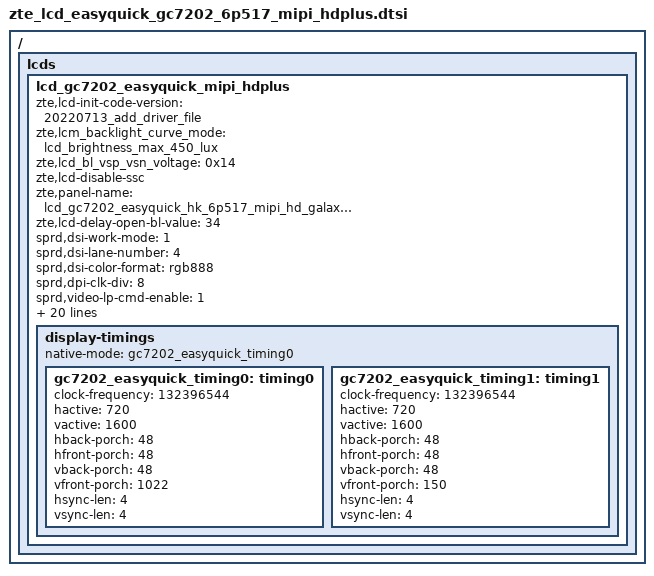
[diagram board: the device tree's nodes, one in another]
/ {
	fragment {
		target-path = "/";
		__overlay__ {
			lcds {
				lcd_gc7202_easyquick_mipi_hdplus: lcd_gc7202_easyquick_mipi_hdplus {
					zte,lcd-init-code-version = "20220713_add_driver_file";

					zte,lcm_backlight_curve_mode = "lcd_brightness_max_450_lux";
					zte,lcd_bl_vsp_vsn_voltage = <0x14>;
					zte,lcd-disable-ssc;
					zte,panel-name = "lcd_gc7202_easyquick_hk_6p517_mipi_hd_galaxycore_4lane";
					zte,lcd-delay-open-bl-value = <34>;

					sprd,dsi-work-mode = <1>;
					sprd,dsi-lane-number = <4>;
					sprd,dsi-color-format = "rgb888";

					sprd,dpi-clk-div = <8>;
					sprd,video-lp-cmd-enable = <1>;
					sprd,hporch-lp-disable = <1>;

					sprd,phy-bit-clock = <1059173>;
					sprd,phy-escape-clock = <20000>;/* kHz */

					sprd,width-mm = <67932>;
					sprd,height-mm = <150960>;

					sprd,esd-check-enable = <1>;/* 0:close , 1:open */
					sprd,esd-check-mode = <1>;/* 0:REG ,1:TE  */
					sprd,esd-check-period = <2000>;

		sprd,reset-on-sequence = <1 10>, <0 10>, <1 35>, <0 10>, <1 10>, <0 10>, <1 10>, <0 10>, <1 30>;
		sprd,reset-off-sequence = <1 10>;
		sprd,use-dcs-write;
		sprd,initial-command = [
39 00 00 04 FF 55 AA 66
15 00 00 02 FF 20
15 00 00 02 FB 00
15 00 00 02 FF 21
15 00 00 02 FB 00
15 00 00 02 FF 22
15 00 00 02 FB 00
15 00 00 02 FF 23
15 00 00 02 FB 00
15 00 00 02 FF 24
15 00 00 02 FB 00
15 00 00 02 FF 26
15 00 00 02 FB 00
15 00 00 02 FF 27
15 00 00 02 FB 00
15 00 00 02 FF A3
15 00 00 02 FB 00
15 00 00 02 FF B3
15 00 00 02 FB 00
15 00 00 02 FF C3
15 00 00 02 FB 00
15 00 00 02 FF 10
15 00 00 02 FB 00
15 00 00 02 FF 20
15 00 00 02 18 44
15 00 00 02 17 52
15 00 00 02 15 5d
15 00 00 02 12 A1
15 00 00 02 A5 00
15 00 00 02 A6 FF
15 00 00 02 A9 00
15 00 00 02 AA FF
15 00 00 02 D3 05
15 00 00 02 2D 1F
15 00 00 02 FF B3
15 00 00 02 58 84
15 00 00 02 82 1A
15 00 00 02 FF 22
15 00 00 02 1F 06
15 00 00 02 FF C3
15 00 00 02 06 44
15 00 00 02 13 07
15 00 00 02 FF 20
15 00 00 02 A3 46
15 00 00 02 A7 46
15 00 00 02 FF B3
15 00 00 02 3F 37
15 00 00 02 5E 10
15 00 00 02 FF 22
15 00 00 02 E4 01
15 00 00 02 01 06
15 00 00 02 02 40
15 00 00 02 25 08
15 00 00 02 26 00
15 00 00 02 2E Aa
15 00 00 02 2F 00
15 00 00 02 36 09
15 00 00 02 37 00
15 00 00 02 3F Aa
15 00 00 02 40 00
15 00 00 02 DC 00
/*15 00 00 02 E0 07//output test pin*/
15 00 00 02 FF 21
15 00 00 02 01 25
15 00 00 02 02 25
15 00 00 02 03 23
15 00 00 02 04 23
15 00 00 02 05 1B
15 00 00 02 06 03
15 00 00 02 07 18
15 00 00 02 08 19
15 00 00 02 09 1A
15 00 00 02 0A 09
15 00 00 02 0B 0B
15 00 00 02 0C 0D
15 00 00 02 0D 0F
15 00 00 02 0E 01
15 00 00 02 0F 25
15 00 00 02 10 25
15 00 00 02 11 25
15 00 00 02 12 25
15 00 00 02 13 25
15 00 00 02 14 25
15 00 00 02 15 25
15 00 00 02 16 25
15 00 00 02 17 23
15 00 00 02 18 23
15 00 00 02 19 23
15 00 00 02 1A 23
15 00 00 02 1B 1B
15 00 00 02 1C 02
15 00 00 02 1D 18
15 00 00 02 1E 19
15 00 00 02 1F 1A
15 00 00 02 20 08
15 00 00 02 21 0A
15 00 00 02 22 0C
15 00 00 02 23 0E
15 00 00 02 24 00
15 00 00 02 25 25
15 00 00 02 26 25
15 00 00 02 27 25
15 00 00 02 28 25
15 00 00 02 29 25
15 00 00 02 2A 25
15 00 00 02 2B 25
15 00 00 02 2D 25
15 00 00 02 7E 03
15 00 00 02 7F 23
15 00 00 02 8B 23
15 00 00 02 80 07
15 00 00 02 8C 03
15 00 00 02 81 03
15 00 00 02 8D 07
15 00 00 02 AF 40
15 00 00 02 B0 40
15 00 00 02 83 02
15 00 00 02 8F 02
15 00 00 02 84 10
15 00 00 02 90 10
15 00 00 02 85 58
15 00 00 02 91 58
15 00 00 02 87 02
15 00 00 02 93 06
15 00 00 02 82 B0
15 00 00 02 8E B0
15 00 00 02 2B 00
15 00 00 02 2E 00
15 00 00 02 88 80
15 00 00 02 89 00
15 00 00 02 8A 00
15 00 00 02 94 80
15 00 00 02 95 00
15 00 00 02 96 00
15 00 00 02 45 0F
15 00 00 02 46 B5
15 00 00 02 4C B5
15 00 00 02 52 B5
15 00 00 02 58 B5
15 00 00 02 47 0A
15 00 00 02 4D 09
15 00 00 02 53 22
15 00 00 02 59 23
15 00 00 02 48 23
15 00 00 02 4E 22
15 00 00 02 54 09
15 00 00 02 5A 0A
15 00 00 02 76 40
15 00 00 02 77 40
15 00 00 02 78 40
15 00 00 02 79 40
15 00 00 02 49 05
15 00 00 02 4A 68
15 00 00 02 4F 05
15 00 00 02 50 68
15 00 00 02 55 60
15 00 00 02 56 60
15 00 00 02 5B 60
15 00 00 02 5C 60
15 00 00 02 BE 03
15 00 00 02 C0 74
15 00 00 02 C1 70
15 00 00 02 BF BB
15 00 00 02 C2 8B
15 00 00 02 C3 8B
15 00 00 02 C6 72
15 00 00 02 C7 54
15 00 00 02 FF 22
15 00 00 02 05 10
15 00 00 02 08 32
15 00 00 02 FF 20
15 00 00 02 25 12
15 00 00 02 FF 20
15 00 00 02 C3 00
15 00 00 02 C4 67
15 00 00 02 C5 00
15 00 00 02 C6 67
15 00 00 02 B3 00
15 00 00 02 B4 28
15 00 00 02 B5 00
15 00 00 02 B6 c0
15 00 00 02 D3 1E
15 00 00 02 FF 20
15 00 00 02 02 36
15 00 00 02 03 36
15 00 00 02 04 57
15 00 00 02 05 57
15 00 00 02 0A 30
15 00 00 02 0B 30
15 00 00 02 0C 54
15 00 00 02 0D 54
15 00 00 02 77 99
15 00 00 02 78 9C
/*15 00 00 02 1C 98
15 00 00 02 1D 98 vcom*/
15 00 00 02 7E 01
15 00 00 02 7F 00
15 00 00 02 80 01
15 00 00 02 81 00
15 00 00 02 82 00
15 00 00 02 83 04
15 00 00 02 84 04
15 00 00 02 85 01
15 00 00 02 86 A4
15 00 00 02 87 01
15 00 00 02 88 8B
15 00 00 02 8A 03
15 00 00 02 8B 03
15 00 00 02 FF 23
15 00 00 02 25 03
39 00 00 11 01 00 00 00 11 00 41 00 5D 00 75 00 87 00 98 00 A6
39 00 00 11 02 00 B6 00 E0 01 02 01 37 01 61 01 A3 01 DD 01 DF
39 00 00 11 03 02 1D 02 68 02 97 02 D5 02 FD 03 3B 03 4B 03 5E
39 00 00 0D 04 03 71 03 88 03 A2 03 C2 03 E9 03 FF
39 00 00 11 0D 00 00 00 11 00 41 00 5D 00 75 00 87 00 98 00 A6
39 00 00 11 0E 00 B6 00 E0 01 02 01 37 01 61 01 A3 01 DD 01 DF
39 00 00 11 0F 02 1D 02 68 02 97 02 D5 02 FD 03 3B 03 4B 03 5E
39 00 00 0D 10 03 71 03 88 03 A2 03 C2 03 E9 03 FF
15 00 00 02 2E 00
15 00 00 02 32 02
15 00 00 02 33 16
15 00 00 02 2D 61
15 00 00 02 FF A3
15 00 00 02 FA 01
15 00 00 02 35 01
15 00 00 02 FF 10
/*39 00 00 03 51 00 FF
15 00 00 02 53 2C
15 00 00 02 55 00*/
15 00 00 02 36 08
15 00 00 02 69 00
15 00 00 02 35 00
15 00 00 02 FF 24
15 00 00 02 7D 55
39 00 00 04 FF 66 99 55
15 00 00 02 FF 10
05 87 00 01 11 
05 14 00 01 29
		];

		sprd,sleep-in-command = [
39 00 00 04 FF 55 AA 66
15 00 00 02 FF 20
15 00 00 02 4A 01
15 00 00 02 48 10
15 00 00 02 49 00
15 00 00 02 FF A3
15 00 00 02 0F 01
15 00 00 02 0E 03
15 00 00 02 FF 10
15 32 00 02 28 00
15 78 00 02 10 00
15 00 00 02 FF A3
15 00 00 02 0F 00
15 00 00 02 0E 00
/* sleep in ,close TP by follow code */
39 00 00 04 FF 55 AA 66
15 00 00 02 FF 26
15 00 00 02 FB 00
39 00 00 05 1D A2 AA AA 0A
15 00 00 02 FF 10
15 00 00 02 FB 00
15 00 00 02 4F 01
			];
		sprd,sleep-out-command = [
			13 78 00 01 11
			13 64 00 01 29
			];
		zte,brightness-levels = [
			39 00 00 03 51 06 66
			];

					display-timings {
						native-mode = <&gc7202_easyquick_timing0>;
						gc7202_easyquick_timing0: timing0 {/*60hz*/
							clock-frequency = <132396544>;
							hactive = <720>;
 							vactive = <1600>;
 							hback-porch = <48>;
 							hfront-porch = <48>;
							vback-porch = <48>;
							vfront-porch = <1022>;
 							hsync-len = <4>;
 							vsync-len = <4>;
 
 						};
						 gc7202_easyquick_timing1: timing1 {/*90hz*/
							clock-frequency = <132396544>;
 							hactive = <720>;
 							vactive = <1600>;
 							hback-porch = <48>;
 							hfront-porch = <48>;
							vback-porch = <48>;
							vfront-porch = <150>;
 							hsync-len = <4>;
 							vsync-len = <4>;
 
						};
					};
					/*
					oled-backlight {
						default-brightness-level = <1632>;
						sprd,max-level = <4095>;
						brightness-levels = [
							39 00 00 03 51 00 00
							39 00 00 02 53 2C
						];
					};*/
				};
			};
		};
	};
};
